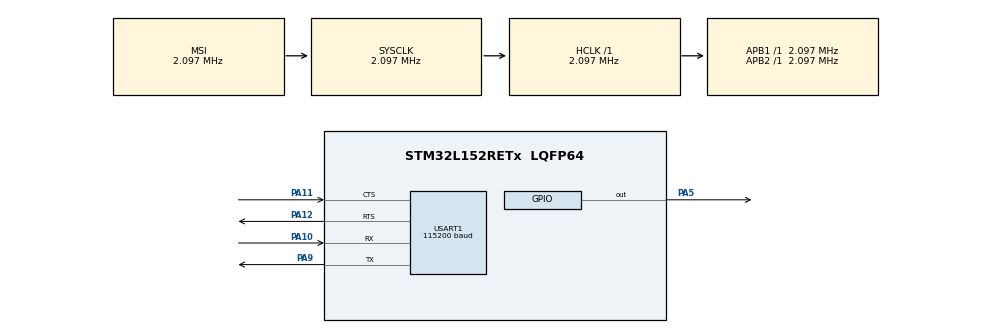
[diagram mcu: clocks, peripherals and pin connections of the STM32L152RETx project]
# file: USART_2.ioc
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Mcu.Family=STM32L1
Mcu.Name=STM32L152RETx
Mcu.Package=LQFP64
NVIC.PriorityGroup=NVIC_PRIORITYGROUP_4
PA10.Mode=Asynchronous
PA10.Signal=USART1_RX
PA11.Mode=CTS_RTS
PA11.Signal=USART1_CTS
PA12.Mode=CTS_RTS
PA12.Signal=USART1_RTS
PA5.Signal=GPIO_Output
PA9.Mode=Asynchronous
PA9.Signal=USART1_TX
ProjectManager.HeapSize=0x200
ProjectManager.StackSize=0x400
ProjectManager.TargetToolchain=MDK-ARM V5.27
RCC.AHBFreq_Value=2097000
RCC.APB1Freq_Value=2097000
RCC.APB2Freq_Value=2097000
RCC.HSE_VALUE=24000000
RCC.HSI_VALUE=16000000
RCC.LSE_VALUE=32768
RCC.MSI_VALUE=2097000
RCC.SYSCLKFreq_VALUE=2097000
RCC.VCOOutputFreq_Value=48000000
USART1.BaudRate=115200
USART1.VirtualMode=VM_ASYNC
board=custom

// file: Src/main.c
/* USER CODE BEGIN Header */
/**
  ******************************************************************************
  * @file           : main.c
  * @brief          : Main program body
  ******************************************************************************
  * @attention
  *
  * <h2><center>&copy; Copyright (c) 2020 STMicroelectronics.
  * All rights reserved.</center></h2>
  *
  * This software component is licensed by ST under BSD 3-Clause license,
  * the "License"; You may not use this file except in compliance with the
  * License. You may obtain a copy of the License at:
  *                        opensource.org/licenses/BSD-3-Clause
  *
  ******************************************************************************
  */
/* USER CODE END Header */

#include "main.h"

/* USER CODE BEGIN PM */
#define PCORE 1
#define SCORE 2
#define REBOT 3
#define STEST 4
#define SLEEP 5
#define KILLD 6
/* USER CODE END PM */

UART_HandleTypeDef huart1;

/* USER CODE BEGIN PV */
uint8_t next_state[2]; //Pcore, Score, sleep, killd, rebot, Stest
uint8_t state[2];
/* USER CODE END PV */

void SystemClock_Config(void);
static void MX_GPIO_Init(void);
static void MX_USART1_UART_Init(void);

/* USER CODE BEGIN 0 */
uint8_t Trigger = 1;
/* USER CODE END 0 */

int main(void)
{
  /* USER CODE BEGIN 1 */
	//Intial for testing
	#if 1
	next_state[0] = PCORE;
	next_state[1] = SCORE;
	#endif
  /* USER CODE END 1 */

  /* MCU Configuration--------------------------------------------------------*/

  /* Reset of all peripherals, Initializes the Flash interface and the Systick. */
  HAL_Init();

  /* Configure the system clock */
  SystemClock_Config();

  /* Initialize all configured peripherals */
  MX_GPIO_Init();
  MX_USART1_UART_Init();

  /* Infinite loop */
  while (1)
  {
		while(HAL_UART_Receive(&huart1, state, 2, 10) != HAL_OK){}
		//Core 2 SM
		if(Trigger == 1){
			if(state[1] == 1)
			{
				next_state[1] = 2;
			}
			else if(state[1] == 2)
			{
				next_state[1] = 1;
			}
		}
		HAL_GPIO_WritePin(GPIOA, GPIO_PIN_5, GPIO_PIN_RESET);
		while(HAL_UART_Transmit(&huart1, next_state, 2, 10) != HAL_OK){}
    /* USER CODE BEGIN 3 */

		HAL_Delay(500);
  }
  /* USER CODE END 3 */
}

void SystemClock_Config(void)
{
  RCC_OscInitTypeDef RCC_OscInitStruct = {0};
  RCC_ClkInitTypeDef RCC_ClkInitStruct = {0};

  /** Configure the main internal regulator output voltage
  */
  __HAL_PWR_VOLTAGESCALING_CONFIG(PWR_REGULATOR_VOLTAGE_SCALE1);
  /** Initializes the CPU, AHB and APB busses clocks
  */
  RCC_OscInitStruct.OscillatorType = RCC_OSCILLATORTYPE_MSI;
  RCC_OscInitStruct.MSIState = RCC_MSI_ON;
  RCC_OscInitStruct.MSICalibrationValue = 0;
  RCC_OscInitStruct.MSIClockRange = RCC_MSIRANGE_5;
  RCC_OscInitStruct.PLL.PLLState = RCC_PLL_NONE;
  if (HAL_RCC_OscConfig(&RCC_OscInitStruct) != HAL_OK)
  {
    Error_Handler();
  }
  /** Initializes the CPU, AHB and APB busses clocks
  */
  RCC_ClkInitStruct.ClockType = RCC_CLOCKTYPE_HCLK|RCC_CLOCKTYPE_SYSCLK
                              |RCC_CLOCKTYPE_PCLK1|RCC_CLOCKTYPE_PCLK2;
  RCC_ClkInitStruct.SYSCLKSource = RCC_SYSCLKSOURCE_MSI;
  RCC_ClkInitStruct.AHBCLKDivider = RCC_SYSCLK_DIV1;
  RCC_ClkInitStruct.APB1CLKDivider = RCC_HCLK_DIV1;
  RCC_ClkInitStruct.APB2CLKDivider = RCC_HCLK_DIV1;

  if (HAL_RCC_ClockConfig(&RCC_ClkInitStruct, FLASH_LATENCY_0) != HAL_OK)
  {
    Error_Handler();
  }
}

static void MX_USART1_UART_Init(void)
{

  huart1.Instance = USART1;
  huart1.Init.BaudRate = 115200;
  huart1.Init.WordLength = UART_WORDLENGTH_8B;
  huart1.Init.StopBits = UART_STOPBITS_1;
  huart1.Init.Parity = UART_PARITY_NONE;
  huart1.Init.Mode = UART_MODE_TX_RX;
  huart1.Init.HwFlowCtl = UART_HWCONTROL_RTS_CTS;
  huart1.Init.OverSampling = UART_OVERSAMPLING_16;
  if (HAL_UART_Init(&huart1) != HAL_OK)
  {
    Error_Handler();
  }

}

static void MX_GPIO_Init(void)
{
  GPIO_InitTypeDef GPIO_InitStruct = {0};

  /* GPIO Ports Clock Enable */
  __HAL_RCC_GPIOA_CLK_ENABLE();

  /*Configure GPIO pin Output Level */
  HAL_GPIO_WritePin(GPIOA, GPIO_PIN_5, GPIO_PIN_RESET);

  /*Configure GPIO pin : PA5 */
  GPIO_InitStruct.Pin = GPIO_PIN_5;
  GPIO_InitStruct.Mode = GPIO_MODE_OUTPUT_PP;
  GPIO_InitStruct.Pull = GPIO_NOPULL;
  GPIO_InitStruct.Speed = GPIO_SPEED_FREQ_LOW;
  HAL_GPIO_Init(GPIOA, &GPIO_InitStruct);

}

void Error_Handler(void)
{
}

/************************ (C) COPYRIGHT STMicroelectronics *****END OF FILE****/
